# CC1314R10 register map
File version: 1.0
CPU: CM33 1.0, other endian, MPU, FPU, 3 interrupt priority bits
Registers are 32-bit, read-write, reset 0x0 unless marked. A register's access mark holds for its fields unless they carry their own. Offsets are from the block's base; [hi:lo] are bit positions; {n}, {i} and the like mark numbered series; 'fields as' and 'values as' point back to an identical list.

## FLASH — Thor1M Flash sub-system registers, includes the NoWrapper Flash Memory Controller (NW), flash read path, and an integrated Efuse controller and EFUSEROM.
Base 0x58030000
0x00 WEPROT_B0_31_0_BY1 reset 0xFFFFFFFF — Internal. Only to be used through TI provided API.
  [31:0] WEPROT_B0_31_0_BY1 — [31:0] Internal. Only to be used through TI provided API.
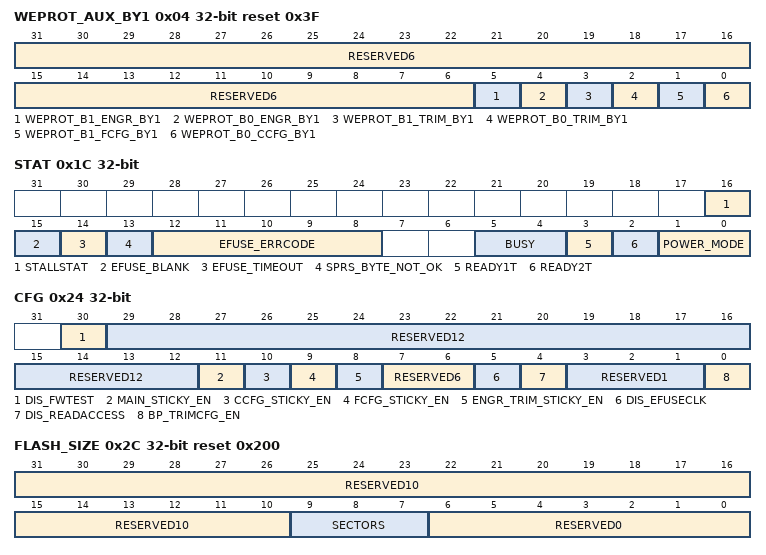
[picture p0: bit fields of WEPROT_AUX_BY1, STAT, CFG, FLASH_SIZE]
0x04 WEPROT_AUX_BY1 reset 0x3F — Internal. Only to be used through TI provided API.
  [31:6] RESERVED6 ro — [31:6] Internal. Only to be used through TI provided API.
  [5] WEPROT_B1_ENGR_BY1 — [5:5] Internal. Only to be used through TI provided API.
  [4] WEPROT_B0_ENGR_BY1 — [4:4] Internal. Only to be used through TI provided API.
  [3] WEPROT_B1_TRIM_BY1 — [3:3] Internal. Only to be used through TI provided API.
  [2] WEPROT_B0_TRIM_BY1 — [2:2] Internal. Only to be used through TI provided API.
  [1] WEPROT_B1_FCFG_BY1 — [1:1] Internal. Only to be used through TI provided API.
  [0] WEPROT_B0_CCFG_BY1 — [0:0] Internal. Only to be used through TI provided API.
0x1C STAT — NW and Efuse Status
  [16] STALLSTAT — [16:16] An ocp1 or ocp3 read stall has occurred. 0 : No stall or stall acknowledged by writing a 1 1 : Stall condition occurred/occurring This is a read/write-clear status bit. It will reset to 0. It will be set when either an ocp1 or ocp3 read occurs to a bank that is presently undergoing a program or write operation. An ocp2 write of 1 to this bit will clear the bit. The ocp2 write will take highest priority in the event an ocp1/ocp3 read is occurring concurrently to the ocp2 write. Clearing the bit should be done only after the ongoing program/erase operation is complete indicating that both banks are free. If clearing occurs while the stall condition persists, the field may get set back to one.
  [15] EFUSE_BLANK ro — [15:15] Efuse scanning detected if fuse ROM is blank: 0 : Not blank 1 : Blank
  [14] EFUSE_TIMEOUT ro — [14:14] Efuse scanning resulted in timeout error. 0 : No Timeout error 1 : Timeout Error
  [13] SPRS_BYTE_NOT_OK ro — [13:13] Efuse scanning resulted in scan chain Sparse byte error. 0 : No Sparse error 1 : Sparse Error
  [12:8] EFUSE_ERRCODE ro — [12:8] Same as EFUSEERROR.CODE
  [5:4] BUSY ro — [5:4] NW FW_SMSTAT.CMD_IN_PROGRESS bit. This flag is valid immediately after the operation setting it 0 : Not busy 1 : Busy Bit 4 is for the busy state for Bank0 which is at logical address 0x0 Bit 5 for Bank1.
  [3] READY1T ro — [3:3] 1T access readiness status indicator from NW. Comes later than 2T readiness. 1: FLASH banks are ready for 1T accesses 0: FLASH banks are not ready for 1T accesses
  [2] READY2T ro — [2:2] 2T access readiness status indicator from NW 1: FLASH banks are ready for 2T accesses 0: FLASH banks are not ready for 2T accesses
  [1:0] POWER_MODE ro — [1:0] Power state of each of the 2 flash arbiter FSM instances in the flash sub-system. For Thor, these bits should mostly be in the same state since both banks are in the same power mode. 0 : Active 1 : Ready for Low power (The 2T readiness has gone low or the flash_off_req has been set=1, and flash_off_ack is ready to be asserted). Bit 0 is for the power state for Bank0 which is at logical address 0x0 Bit 1 for Bank1
0x24 CFG — Internal. Only to be used through TI provided API.
  [30] DIS_FWTEST — [30:30] Internal. Only to be used through TI provided API.
  [29:12] RESERVED12 ro — [29:12] Internal. Only to be used through TI provided API.
  [11] MAIN_STICKY_EN — [11:11] Internal. Only to be used through TI provided API.
  [10] CCFG_STICKY_EN — [10:10] Internal. Only to be used through TI provided API.
  [9] FCFG_STICKY_EN — [9:9] Internal. Only to be used through TI provided API.
  [8] ENGR_TRIM_STICKY_EN — [8:8] Internal. Only to be used through TI provided API.
  [7:6] RESERVED6 ro — [7:6] Internal. Only to be used through TI provided API.
  [5] DIS_EFUSECLK — [5:5] Internal. Only to be used through TI provided API.
  [4] DIS_READACCESS — [4:4] Internal. Only to be used through TI provided API.
  [3:1] RESERVED1 — [3:1] Internal. Only to be used through TI provided API.
  [0] BP_TRIMCFG_EN — [0:0] Internal. Only to be used through TI provided API.
0x2C FLASH_SIZE reset 0x200 — Internal. Only to be used through TI provided API.
  [31:10] RESERVED10 ro — [31:10] Internal. Only to be used through TI provided API.
  [9:7] SECTORS — [9:7] Internal. Only to be used through TI provided API.
  [6:0] RESERVED0 ro — [6:0] Internal. Only to be used through TI provided API.
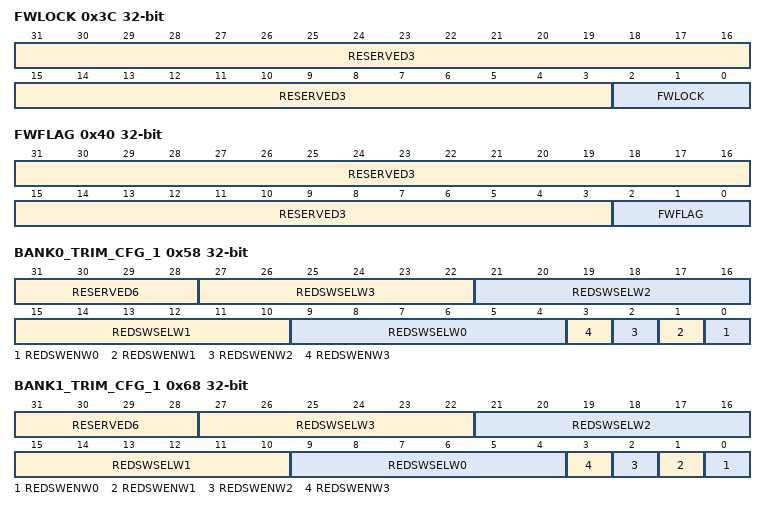
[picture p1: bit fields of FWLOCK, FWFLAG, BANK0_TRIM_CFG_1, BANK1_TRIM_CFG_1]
0x3C FWLOCK — Internal. Only to be used through TI provided API.
  [31:3] RESERVED3 ro — [31:3] Internal. Only to be used through TI provided API.
  [2:0] FWLOCK — [2:0] Internal. Only to be used through TI provided API.
0x40 FWFLAG — Internal. Only to be used through TI provided API.
  [31:3] RESERVED3 ro — [31:3] Internal. Only to be used through TI provided API.
  [2:0] FWFLAG — [2:0] Internal. Only to be used through TI provided API.
0x50 BANK0_TRIM_CFG_3 — Internal. Only to be used through TI provided API.
  [31:0] RESERVED32 — [31:0] Internal. Only to be used through TI provided API.
0x54 BANK0_TRIM_CFG_2 — Internal. Only to be used through TI provided API.
  fields as BANK0_TRIM_CFG_3
0x58 BANK0_TRIM_CFG_1 — Internal. Only to be used through TI provided API.
  [31:28] RESERVED6 — [31:28] Internal. Only to be used through TI provided API.
  [6n+9:6n+4] REDSWSELW{n} (n=0..3) — [{6n+9}:{6n+4}] Internal. Only to be used through TI provided API.
  [n] REDSWENW{n} (n=0..3) — [{n}:{n}] Internal. Only to be used through TI provided API.
0x5C BANK0_TRIM_CFG_0 — Internal. Only to be used through TI provided API.
  [31:0] BANK0_TRIM_CFG_0 — [31:0] Internal. Only to be used through TI provided API.
0x60 BANK1_TRIM_CFG_3 — Internal. Only to be used through TI provided API.
  fields as BANK0_TRIM_CFG_3
0x64 BANK1_TRIM_CFG_2 — Internal. Only to be used through TI provided API.
  fields as BANK0_TRIM_CFG_3
0x68 BANK1_TRIM_CFG_1 — Internal. Only to be used through TI provided API.
  fields as BANK0_TRIM_CFG_1
0x6C BANK1_TRIM_CFG_0 — Internal. Only to be used through TI provided API.
  [31:0] BANK1_TRIM_CFG_0 — [31:0] Internal. Only to be used through TI provided API.
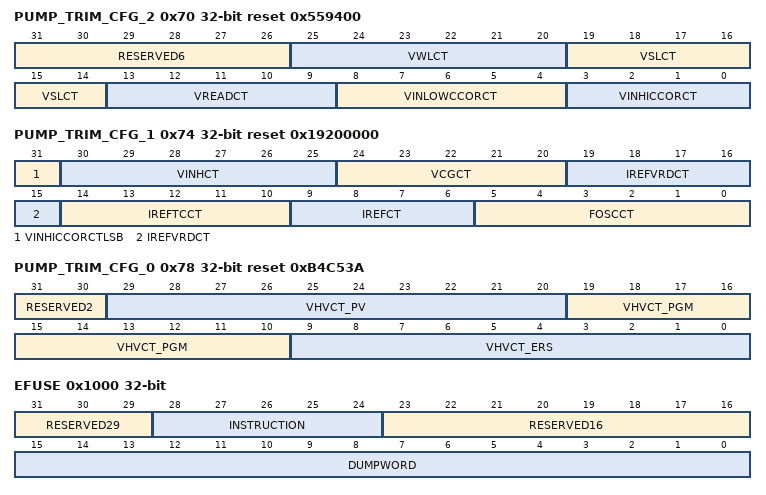
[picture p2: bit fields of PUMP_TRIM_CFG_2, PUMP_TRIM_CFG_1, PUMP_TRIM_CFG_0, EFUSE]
0x70 PUMP_TRIM_CFG_2 reset 0x559400 — Internal. Only to be used through TI provided API.
  [31:26] RESERVED6 — [31:26] Internal. Only to be used through TI provided API.
  [25:20] VWLCT — [25:20] Internal. Only to be used through TI provided API.
  [19:14] VSLCT — [19:14] Internal. Only to be used through TI provided API.
  [13:9] VREADCT — [13:9] Internal. Only to be used through TI provided API.
  [8:4] VINLOWCCORCT — [8:4] Internal. Only to be used through TI provided API.
  [3:0] VINHICCORCT — [3:0] Internal. Only to be used through TI provided API.
0x74 PUMP_TRIM_CFG_1 reset 0x19200000 — Internal. Only to be used through TI provided API.
  [31] VINHICCORCTLSB — [31:31] Internal. Only to be used through TI provided API.
  [30:25] VINHCT — [30:25] Internal. Only to be used through TI provided API.
  [24:20] VCGCT — [24:20] Internal. Only to be used through TI provided API.
  [19:15] IREFVRDCT — [19:15] Internal. Only to be used through TI provided API.
  [14:10] IREFTCCT — [14:10] Internal. Only to be used through TI provided API.
  [9:6] IREFCT — [9:6] Internal. Only to be used through TI provided API.
  [5:0] FOSCCT — [5:0] Internal. Only to be used through TI provided API.
0x78 PUMP_TRIM_CFG_0 reset 0xB4C53A — Internal. Only to be used through TI provided API.
  [31:30] RESERVED2 — [31:30] Internal. Only to be used through TI provided API.
  [29:20] VHVCT_PV — [29:20] Internal. Only to be used through TI provided API.
  [19:10] VHVCT_PGM — [19:10] Internal. Only to be used through TI provided API.
  [9:0] VHVCT_ERS — [9:0] Internal. Only to be used through TI provided API.
0x1000 EFUSE — Internal. Only to be used through TI provided API.
  [31:29] RESERVED29 ro — [31:29] Internal. Only to be used through TI provided API.
  [28:24] INSTRUCTION — [28:24] Internal. Only to be used through TI provided API.
  [23:16] RESERVED16 ro — [23:16] Internal. Only to be used through TI provided API.
  [15:0] DUMPWORD — [15:0] Internal. Only to be used through TI provided API.
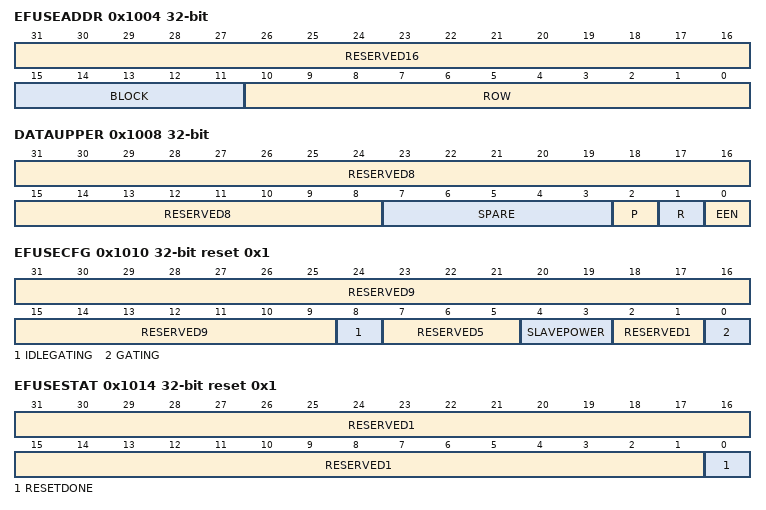
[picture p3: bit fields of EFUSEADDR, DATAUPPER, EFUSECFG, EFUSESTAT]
0x1004 EFUSEADDR — Internal. Only to be used through TI provided API.
  [31:16] RESERVED16 ro — [31:16] Internal. Only to be used through TI provided API.
  [15:11] BLOCK — [15:11] Internal. Only to be used through TI provided API.
  [10:0] ROW — [10:0] Internal. Only to be used through TI provided API.
0x1008 DATAUPPER — Internal. Only to be used through TI provided API.
  [31:8] RESERVED8 ro — [31:8] Internal. Only to be used through TI provided API.
  [7:3] SPARE — [7:3] Internal. Only to be used through TI provided API.
  [2] P — [2:2] Internal. Only to be used through TI provided API.
  [1] R — [1:1] Internal. Only to be used through TI provided API.
  [0] EEN — [0:0] Internal. Only to be used through TI provided API.
0x100C DATALOWER — Internal. Only to be used through TI provided API.
  [31:0] DATA — [31:0] Internal. Only to be used through TI provided API.
0x1010 EFUSECFG reset 0x1 — Internal. Only to be used through TI provided API.
  [31:9] RESERVED9 ro — [31:9] Internal. Only to be used through TI provided API.
  [8] IDLEGATING — [8:8] Internal. Only to be used through TI provided API.
  [7:5] RESERVED5 ro — [7:5] Internal. Only to be used through TI provided API.
  [4:3] SLAVEPOWER — [4:3] Internal. Only to be used through TI provided API.
  [2:1] RESERVED1 ro — [2:1] Internal. Only to be used through TI provided API.
  [0] GATING — [0:0] Internal. Only to be used through TI provided API.
0x1014 EFUSESTAT reset 0x1 — Internal. Only to be used through TI provided API.
  [31:1] RESERVED1 ro — [31:1] Internal. Only to be used through TI provided API.
  [0] RESETDONE ro — [0:0] Internal. Only to be used through TI provided API.
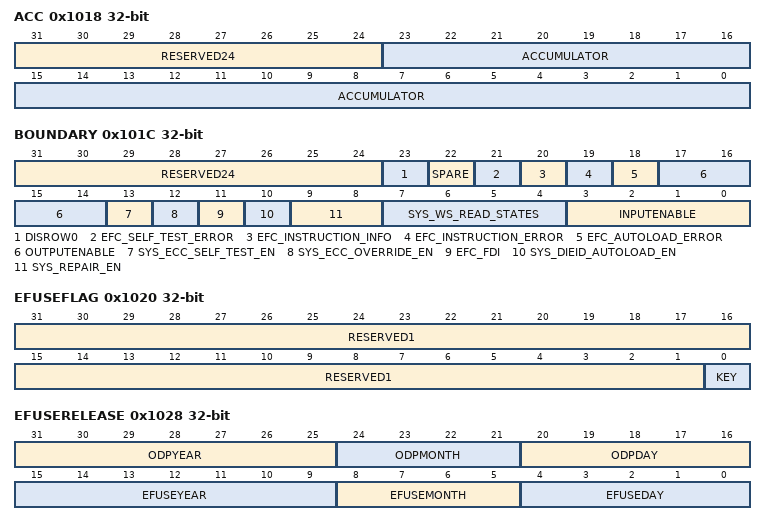
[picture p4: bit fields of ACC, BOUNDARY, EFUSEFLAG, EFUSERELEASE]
0x1018 ACC — Internal. Only to be used through TI provided API.
  [31:24] RESERVED24 ro — [31:24] Internal. Only to be used through TI provided API.
  [23:0] ACCUMULATOR ro — [23:0] Internal. Only to be used through TI provided API.
0x101C BOUNDARY — Internal. Only to be used through TI provided API.
  [31:24] RESERVED24 ro — [31:24] Internal. Only to be used through TI provided API.
  [23] DISROW0 — [23:23] Internal. Only to be used through TI provided API.
  [22] SPARE — [22:22] Internal. Only to be used through TI provided API.
  [21] EFC_SELF_TEST_ERROR — [21:21] Internal. Only to be used through TI provided API.
  [20] EFC_INSTRUCTION_INFO — [20:20] Internal. Only to be used through TI provided API.
  [19] EFC_INSTRUCTION_ERROR — [19:19] Internal. Only to be used through TI provided API.
  [18] EFC_AUTOLOAD_ERROR — [18:18] Internal. Only to be used through TI provided API.
  [17:14] OUTPUTENABLE — [17:14] Internal. Only to be used through TI provided API.
  [13] SYS_ECC_SELF_TEST_EN — [13:13] Internal. Only to be used through TI provided API.
  [12] SYS_ECC_OVERRIDE_EN — [12:12] Internal. Only to be used through TI provided API.
  [11] EFC_FDI — [11:11] Internal. Only to be used through TI provided API.
  [10] SYS_DIEID_AUTOLOAD_EN — [10:10] Internal. Only to be used through TI provided API.
  [9:8] SYS_REPAIR_EN — [9:8] Internal. Only to be used through TI provided API.
  [7:4] SYS_WS_READ_STATES — [7:4] Internal. Only to be used through TI provided API.
  [3:0] INPUTENABLE — [3:0] Internal. Only to be used through TI provided API.
0x1020 EFUSEFLAG — Internal. Only to be used through TI provided API.
  [31:1] RESERVED1 ro — [31:1] Internal. Only to be used through TI provided API.
  [0] KEY ro — [0:0] Internal. Only to be used through TI provided API.
0x1024 EFUSEKEY — Internal. Only to be used through TI provided API.
  [31:0] CODE — [31:0] Internal. Only to be used through TI provided API.
0x1028 EFUSERELEASE — Internal. Only to be used through TI provided API.
  [31:25] ODPYEAR ro — [31:25] Internal. Only to be used through TI provided API.
  [24:21] ODPMONTH ro — [24:21] Internal. Only to be used through TI provided API.
  [20:16] ODPDAY ro — [20:16] Internal. Only to be used through TI provided API.
  [15:9] EFUSEYEAR ro — [15:9] Internal. Only to be used through TI provided API.
  [8:5] EFUSEMONTH ro — [8:5] Internal. Only to be used through TI provided API.
  [4:0] EFUSEDAY ro — [4:0] Internal. Only to be used through TI provided API.
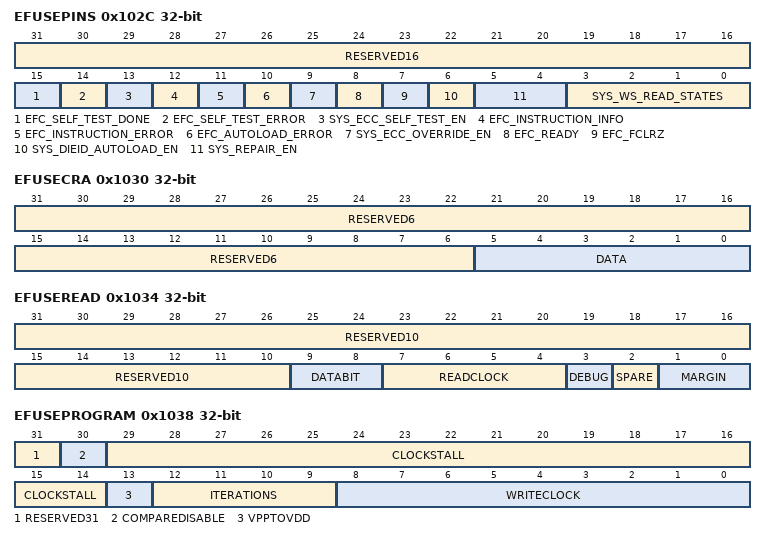
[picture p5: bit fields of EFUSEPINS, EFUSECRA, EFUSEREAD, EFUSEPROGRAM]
0x102C EFUSEPINS — Internal. Only to be used through TI provided API.
  [31:16] RESERVED16 ro — [31:16] Internal. Only to be used through TI provided API.
  [15] EFC_SELF_TEST_DONE ro — [15:15] Internal. Only to be used through TI provided API.
  [14] EFC_SELF_TEST_ERROR ro — [14:14] Internal. Only to be used through TI provided API.
  [13] SYS_ECC_SELF_TEST_EN ro — [13:13] Internal. Only to be used through TI provided API.
  [12] EFC_INSTRUCTION_INFO ro — [12:12] Internal. Only to be used through TI provided API.
  [11] EFC_INSTRUCTION_ERROR ro — [11:11] Internal. Only to be used through TI provided API.
  [10] EFC_AUTOLOAD_ERROR ro — [10:10] Internal. Only to be used through TI provided API.
  [9] SYS_ECC_OVERRIDE_EN ro — [9:9] Internal. Only to be used through TI provided API.
  [8] EFC_READY ro — [8:8] Internal. Only to be used through TI provided API.
  [7] EFC_FCLRZ ro — [7:7] Internal. Only to be used through TI provided API.
  [6] SYS_DIEID_AUTOLOAD_EN ro — [6:6] Internal. Only to be used through TI provided API.
  [5:4] SYS_REPAIR_EN ro — [5:4] Internal. Only to be used through TI provided API.
  [3:0] SYS_WS_READ_STATES ro — [3:0] Internal. Only to be used through TI provided API.
0x1030 EFUSECRA — Internal. Only to be used through TI provided API.
  [31:6] RESERVED6 ro — [31:6] Internal. Only to be used through TI provided API.
  [5:0] DATA — [5:0] Internal. Only to be used through TI provided API.
0x1034 EFUSEREAD — Internal. Only to be used through TI provided API.
  [31:10] RESERVED10 ro — [31:10] Internal. Only to be used through TI provided API.
  [9:8] DATABIT — [9:8] Internal. Only to be used through TI provided API.
  [7:4] READCLOCK — [7:4] Internal. Only to be used through TI provided API.
  [3] DEBUG — [3:3] Internal. Only to be used through TI provided API.
  [2] SPARE — [2:2] Internal. Only to be used through TI provided API.
  [1:0] MARGIN — [1:0] Internal. Only to be used through TI provided API.
0x1038 EFUSEPROGRAM — Internal. Only to be used through TI provided API.
  [31] RESERVED31 ro — [31:31] Internal. Only to be used through TI provided API.
  [30] COMPAREDISABLE — [30:30] Internal. Only to be used through TI provided API.
  [29:14] CLOCKSTALL — [29:14] Internal. Only to be used through TI provided API.
  [13] VPPTOVDD — [13:13] Internal. Only to be used through TI provided API.
  [12:9] ITERATIONS — [12:9] Internal. Only to be used through TI provided API.
  [8:0] WRITECLOCK — [8:0] Internal. Only to be used through TI provided API.
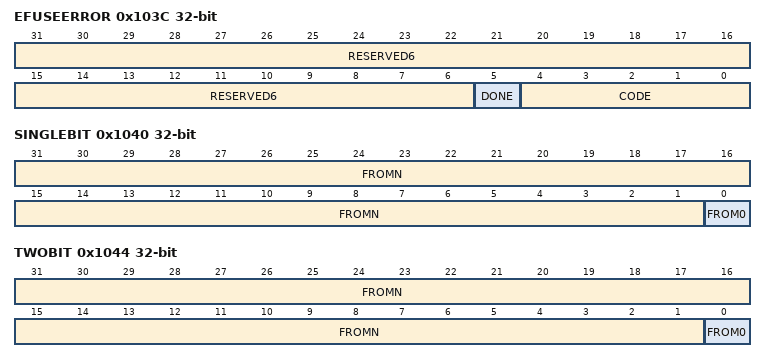
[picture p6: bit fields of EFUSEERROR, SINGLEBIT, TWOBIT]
0x103C EFUSEERROR — Internal. Only to be used through TI provided API.
  [31:6] RESERVED6 ro — [31:6] Internal. Only to be used through TI provided API.
  [5] DONE — [5:5] Internal. Only to be used through TI provided API.
  [4:0] CODE — [4:0] Internal. Only to be used through TI provided API.
0x1040 SINGLEBIT — Internal. Only to be used through TI provided API.
  [31:1] FROMN ro — [31:1] Internal. Only to be used through TI provided API.
  [0] FROM0 ro — [0:0] Internal. Only to be used through TI provided API.
0x1044 TWOBIT — Internal. Only to be used through TI provided API.
  fields as SINGLEBIT
0x1048 SELFTESTCYC — Internal. Only to be used through TI provided API.
  [31:0] CYCLES — [31:0] Internal. Only to be used through TI provided API.
0x104C SELFTESTSIGN — Internal. Only to be used through TI provided API.
  [31:0] SIGNATURE — [31:0] Internal. Only to be used through TI provided API.
